# STM32MP13xx register map
File version: 1.7
CPU: CA7 r0p0, little endian, MPU, FPU, 4 interrupt priority bits
Registers are 32-bit, read-write, reset 0x0 unless marked. A register's access mark holds for its fields unless they carry their own. Offsets are from the block's base; [hi:lo] are bit positions; {n}, {i} and the like mark numbered series; 'fields as' and 'values as' point back to an identical list; <NAME> marks a mode.

## DMA1
Base 0x48000000
Same registers: DMA2 0x48001000, DMA3 0x48005000
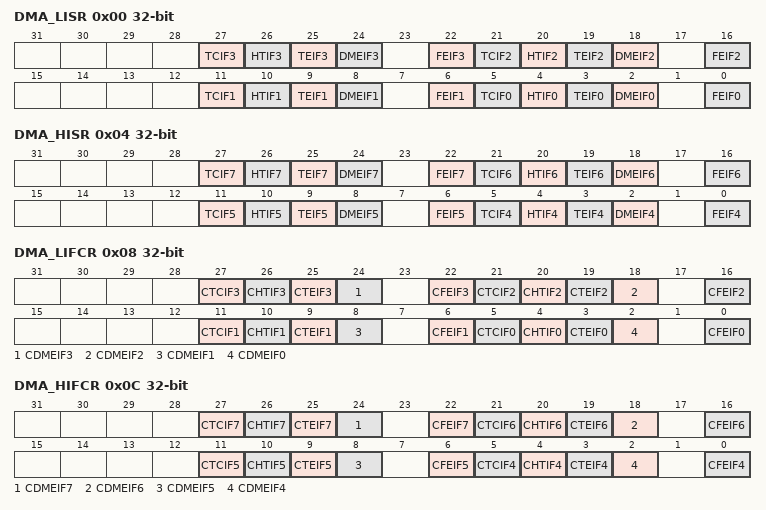
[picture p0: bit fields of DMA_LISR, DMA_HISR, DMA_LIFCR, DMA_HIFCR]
0x00 DMA_LISR ro — DMA low interrupt status register
  [27] TCIF3 — stream x transfer complete interrupt flag (x = 3 to 0) This bit is set by hardware. It is cleared by software writing 1 to the corresponding bit in the DMA_LIFCR register.
    0=no transfer complete event on stream x; 1=a transfer complete event occurred on stream x
  [26] HTIF3 — stream x half transfer interrupt flag (x = 3 to 0) This bit is set by hardware. It is cleared by software writing 1 to the corresponding bit in the DMA_LIFCR register.
    0=no half transfer event on stream x; 1=a half transfer event occurred on stream x
  [25] TEIF3 — stream x transfer error interrupt flag (x = 3 to 0) This bit is set by hardware. It is cleared by software writing 1 to the corresponding bit in the DMA_LIFCR register.
    0=no transfer error on stream x; 1=a transfer error occurred on stream x
  [24] DMEIF3 — stream x direct mode error interrupt flag (x = 3 to 0) This bit is set by hardware. It is cleared by software writing 1 to the corresponding bit in the DMA_LIFCR register.
    0=No direct mode error on stream x; 1=a direct mode error occurred on stream x
  [22] FEIF3 — stream x FIFO error interrupt flag (x = 3 to 0) This bit is set by hardware. It is cleared by software writing 1 to the corresponding bit in the DMA_LIFCR register.
    0=no FIFO error event on stream x; 1=a FIFO error event occurred on stream x
  [21] TCIF2 — stream x transfer complete interrupt flag (x = 3 to 0) This bit is set by hardware. It is cleared by software writing 1 to the corresponding bit in the DMA_LIFCR register.
    values as TCIF3
  [20] HTIF2 — stream x half transfer interrupt flag (x = 3 to 0) This bit is set by hardware. It is cleared by software writing 1 to the corresponding bit in the DMA_LIFCR register.
    values as HTIF3
  [19] TEIF2 — stream x transfer error interrupt flag (x = 3 to 0) This bit is set by hardware. It is cleared by software writing 1 to the corresponding bit in the DMA_LIFCR register.
    values as TEIF3
  [18] DMEIF2 — stream x direct mode error interrupt flag (x = 3 to 0) This bit is set by hardware. It is cleared by software writing 1 to the corresponding bit in the DMA_LIFCR register.
    values as DMEIF3
  [16] FEIF2 — stream x FIFO error interrupt flag (x = 3 to 0) This bit is set by hardware. It is cleared by software writing 1 to the corresponding bit in the DMA_LIFCR register.
    values as FEIF3
  [11] TCIF1 — stream x transfer complete interrupt flag (x = 3 to 0) This bit is set by hardware. It is cleared by software writing 1 to the corresponding bit in the DMA_LIFCR register.
    values as TCIF3
  [10] HTIF1 — stream x half transfer interrupt flag (x = 3 to 0) This bit is set by hardware. It is cleared by software writing 1 to the corresponding bit in the DMA_LIFCR register.
    values as HTIF3
  [9] TEIF1 — stream x transfer error interrupt flag (x = 3 to 0) This bit is set by hardware. It is cleared by software writing 1 to the corresponding bit in the DMA_LIFCR register.
    values as TEIF3
  [8] DMEIF1 — stream x direct mode error interrupt flag (x = 3 to 0) This bit is set by hardware. It is cleared by software writing 1 to the corresponding bit in the DMA_LIFCR register.
    values as DMEIF3
  [6] FEIF1 — stream x FIFO error interrupt flag (x = 3 to 0) This bit is set by hardware. It is cleared by software writing 1 to the corresponding bit in the DMA_LIFCR register.
    values as FEIF3
  [5] TCIF0 — stream x transfer complete interrupt flag (x = 3 to 0) This bit is set by hardware. It is cleared by software writing 1 to the corresponding bit in the DMA_LIFCR register.
    values as TCIF3
  [4] HTIF0 — stream x half transfer interrupt flag (x = 3 to 0) This bit is set by hardware. It is cleared by software writing 1 to the corresponding bit in the DMA_LIFCR register.
    values as HTIF3
  [3] TEIF0 — stream x transfer error interrupt flag (x = 3 to 0) This bit is set by hardware. It is cleared by software writing 1 to the corresponding bit in the DMA_LIFCR register.
    values as TEIF3
  [2] DMEIF0 — stream x direct mode error interrupt flag (x = 3 to 0) This bit is set by hardware. It is cleared by software writing 1 to the corresponding bit in the DMA_LIFCR register.
    values as DMEIF3
  [0] FEIF0 — stream x FIFO error interrupt flag (x = 3 to 0) This bit is set by hardware. It is cleared by software writing 1 to the corresponding bit in the DMA_LIFCR register.
    values as FEIF3
0x04 DMA_HISR ro — DMA high interrupt status register
  [27] TCIF7 — stream x transfer complete interrupt flag (x = 7 to 4) This bit is set by hardware. It is cleared by software writing 1 to the corresponding bit in the DMA_HIFCR register.
    values as DMA_LISR.TCIF3
  [26] HTIF7 — stream x half transfer interrupt flag (x = 7 to 4) This bit is set by hardware. It is cleared by software writing 1 to the corresponding bit in the DMA_HIFCR register.
    values as DMA_LISR.HTIF3
  [25] TEIF7 — stream x transfer error interrupt flag (x = 7 to 4) This bit is set by hardware. It is cleared by software writing 1 to the corresponding bit in the DMA_HIFCR register.
    values as DMA_LISR.TEIF3
  [24] DMEIF7 — stream x direct mode error interrupt flag (x = 7 to 4) This bit is set by hardware. It is cleared by software writing 1 to the corresponding bit in the DMA_HIFCR register.
    0=no direct mode error on stream x; 1=a direct mode error occurred on stream x
  [22] FEIF7 — stream x FIFO error interrupt flag (x = 7 to 4) This bit is set by hardware. It is cleared by software writing 1 to the corresponding bit in the DMA_HIFCR register.
    values as DMA_LISR.FEIF3
  [21] TCIF6 — stream x transfer complete interrupt flag (x = 7 to 4) This bit is set by hardware. It is cleared by software writing 1 to the corresponding bit in the DMA_HIFCR register.
    values as DMA_LISR.TCIF3
  [20] HTIF6 — stream x half transfer interrupt flag (x = 7 to 4) This bit is set by hardware. It is cleared by software writing 1 to the corresponding bit in the DMA_HIFCR register.
    values as DMA_LISR.HTIF3
  [19] TEIF6 — stream x transfer error interrupt flag (x = 7 to 4) This bit is set by hardware. It is cleared by software writing 1 to the corresponding bit in the DMA_HIFCR register.
    values as DMA_LISR.TEIF3
  [18] DMEIF6 — stream x direct mode error interrupt flag (x = 7 to 4) This bit is set by hardware. It is cleared by software writing 1 to the corresponding bit in the DMA_HIFCR register.
    values as DMEIF7
  [16] FEIF6 — stream x FIFO error interrupt flag (x = 7 to 4) This bit is set by hardware. It is cleared by software writing 1 to the corresponding bit in the DMA_HIFCR register.
    values as DMA_LISR.FEIF3
  [11] TCIF5 — stream x transfer complete interrupt flag (x = 7 to 4) This bit is set by hardware. It is cleared by software writing 1 to the corresponding bit in the DMA_HIFCR register.
    values as DMA_LISR.TCIF3
  [10] HTIF5 — stream x half transfer interrupt flag (x = 7 to 4) This bit is set by hardware. It is cleared by software writing 1 to the corresponding bit in the DMA_HIFCR register.
    values as DMA_LISR.HTIF3
  [9] TEIF5 — stream x transfer error interrupt flag (x = 7 to 4) This bit is set by hardware. It is cleared by software writing 1 to the corresponding bit in the DMA_HIFCR register.
    values as DMA_LISR.TEIF3
  [8] DMEIF5 — stream x direct mode error interrupt flag (x = 7 to 4) This bit is set by hardware. It is cleared by software writing 1 to the corresponding bit in the DMA_HIFCR register.
    values as DMEIF7
  [6] FEIF5 — stream x FIFO error interrupt flag (x = 7 to 4) This bit is set by hardware. It is cleared by software writing 1 to the corresponding bit in the DMA_HIFCR register.
    values as DMA_LISR.FEIF3
  [5] TCIF4 — stream x transfer complete interrupt flag (x = 7 to 4) This bit is set by hardware. It is cleared by software writing 1 to the corresponding bit in the DMA_HIFCR register.
    values as DMA_LISR.TCIF3
  [4] HTIF4 — stream x half transfer interrupt flag (x = 7 to 4) This bit is set by hardware. It is cleared by software writing 1 to the corresponding bit in the DMA_HIFCR register.
    values as DMA_LISR.HTIF3
  [3] TEIF4 — stream x transfer error interrupt flag (x = 7 to 4) This bit is set by hardware. It is cleared by software writing 1 to the corresponding bit in the DMA_HIFCR register.
    values as DMA_LISR.TEIF3
  [2] DMEIF4 — stream x direct mode error interrupt flag (x = 7 to 4) This bit is set by hardware. It is cleared by software writing 1 to the corresponding bit in the DMA_HIFCR register.
    values as DMEIF7
  [0] FEIF4 — stream x FIFO error interrupt flag (x = 7 to 4) This bit is set by hardware. It is cleared by software writing 1 to the corresponding bit in the DMA_HIFCR register.
    values as DMA_LISR.FEIF3
0x08 DMA_LIFCR wo — DMA low interrupt flag clear register
  [27] CTCIF3 — stream x clear transfer complete interrupt flag (x = 3 to 0) Writing 1 to this bit clears the corresponding TCIFx flag in the DMA_LISR register.
  [26] CHTIF3 — stream x clear half transfer interrupt flag (x = 3 to 0) Writing 1 to this bit clears the corresponding HTIFx flag in the DMA_LISR register
  [25] CTEIF3 — Stream x clear transfer error interrupt flag (x = 3 to 0) Writing 1 to this bit clears the corresponding TEIFx flag in the DMA_LISR register.
  [24] CDMEIF3 — stream x clear direct mode error interrupt flag (x = 3 to 0) Writing 1 to this bit clears the corresponding DMEIFx flag in the DMA_LISR register.
  [22] CFEIF3 — stream x clear FIFO error interrupt flag (x = 3 to 0) Writing 1 to this bit clears the corresponding CFEIFx flag in the DMA_LISR register.
  [21] CTCIF2 — stream x clear transfer complete interrupt flag (x = 3 to 0) Writing 1 to this bit clears the corresponding TCIFx flag in the DMA_LISR register.
  [20] CHTIF2 — stream x clear half transfer interrupt flag (x = 3 to 0) Writing 1 to this bit clears the corresponding HTIFx flag in the DMA_LISR register
  [19] CTEIF2 — Stream x clear transfer error interrupt flag (x = 3 to 0) Writing 1 to this bit clears the corresponding TEIFx flag in the DMA_LISR register.
  [18] CDMEIF2 — stream x clear direct mode error interrupt flag (x = 3 to 0) Writing 1 to this bit clears the corresponding DMEIFx flag in the DMA_LISR register.
  [16] CFEIF2 — stream x clear FIFO error interrupt flag (x = 3 to 0) Writing 1 to this bit clears the corresponding CFEIFx flag in the DMA_LISR register.
  [11] CTCIF1 — stream x clear transfer complete interrupt flag (x = 3 to 0) Writing 1 to this bit clears the corresponding TCIFx flag in the DMA_LISR register.
  [10] CHTIF1 — stream x clear half transfer interrupt flag (x = 3 to 0) Writing 1 to this bit clears the corresponding HTIFx flag in the DMA_LISR register
  [9] CTEIF1 — Stream x clear transfer error interrupt flag (x = 3 to 0) Writing 1 to this bit clears the corresponding TEIFx flag in the DMA_LISR register.
  [8] CDMEIF1 — stream x clear direct mode error interrupt flag (x = 3 to 0) Writing 1 to this bit clears the corresponding DMEIFx flag in the DMA_LISR register.
  [6] CFEIF1 — stream x clear FIFO error interrupt flag (x = 3 to 0) Writing 1 to this bit clears the corresponding CFEIFx flag in the DMA_LISR register.
  [5] CTCIF0 — stream x clear transfer complete interrupt flag (x = 3 to 0) Writing 1 to this bit clears the corresponding TCIFx flag in the DMA_LISR register.
  [4] CHTIF0 — stream x clear half transfer interrupt flag (x = 3 to 0) Writing 1 to this bit clears the corresponding HTIFx flag in the DMA_LISR register
  [3] CTEIF0 — Stream x clear transfer error interrupt flag (x = 3 to 0) Writing 1 to this bit clears the corresponding TEIFx flag in the DMA_LISR register.
  [2] CDMEIF0 — stream x clear direct mode error interrupt flag (x = 3 to 0) Writing 1 to this bit clears the corresponding DMEIFx flag in the DMA_LISR register.
  [0] CFEIF0 — stream x clear FIFO error interrupt flag (x = 3 to 0) Writing 1 to this bit clears the corresponding CFEIFx flag in the DMA_LISR register.
0x0C DMA_HIFCR wo — DMA high interrupt flag clear register
  [27] CTCIF7 — stream x clear transfer complete interrupt flag (x = 7 to 4) Writing 1 to this bit clears the corresponding TCIFx flag in the DMA_HISR register.
  [26] CHTIF7 — stream x clear half transfer interrupt flag (x = 7 to 4) Writing 1 to this bit clears the corresponding HTIFx flag in the DMA_HISR register.
  [25] CTEIF7 — stream x clear transfer error interrupt flag (x = 7 to 4) Writing 1 to this bit clears the corresponding TEIFx flag in the DMA_HISR register.
  [24] CDMEIF7 — stream x clear direct mode error interrupt flag (x = 7 to 4) Writing 1 to this bit clears the corresponding DMEIFx flag in the DMA_HISR register.
  [22] CFEIF7 — stream x clear FIFO error interrupt flag (x = 7 to 4) Writing 1 to this bit clears the corresponding CFEIFx flag in the DMA_HISR register.
  [21] CTCIF6 — stream x clear transfer complete interrupt flag (x = 7 to 4) Writing 1 to this bit clears the corresponding TCIFx flag in the DMA_HISR register.
  [20] CHTIF6 — stream x clear half transfer interrupt flag (x = 7 to 4) Writing 1 to this bit clears the corresponding HTIFx flag in the DMA_HISR register.
  [19] CTEIF6 — stream x clear transfer error interrupt flag (x = 7 to 4) Writing 1 to this bit clears the corresponding TEIFx flag in the DMA_HISR register.
  [18] CDMEIF6 — stream x clear direct mode error interrupt flag (x = 7 to 4) Writing 1 to this bit clears the corresponding DMEIFx flag in the DMA_HISR register.
  [16] CFEIF6 — stream x clear FIFO error interrupt flag (x = 7 to 4) Writing 1 to this bit clears the corresponding CFEIFx flag in the DMA_HISR register.
  [11] CTCIF5 — stream x clear transfer complete interrupt flag (x = 7 to 4) Writing 1 to this bit clears the corresponding TCIFx flag in the DMA_HISR register.
  [10] CHTIF5 — stream x clear half transfer interrupt flag (x = 7 to 4) Writing 1 to this bit clears the corresponding HTIFx flag in the DMA_HISR register.
  [9] CTEIF5 — stream x clear transfer error interrupt flag (x = 7 to 4) Writing 1 to this bit clears the corresponding TEIFx flag in the DMA_HISR register.
  [8] CDMEIF5 — stream x clear direct mode error interrupt flag (x = 7 to 4) Writing 1 to this bit clears the corresponding DMEIFx flag in the DMA_HISR register.
  [6] CFEIF5 — stream x clear FIFO error interrupt flag (x = 7 to 4) Writing 1 to this bit clears the corresponding CFEIFx flag in the DMA_HISR register.
  [5] CTCIF4 — stream x clear transfer complete interrupt flag (x = 7 to 4) Writing 1 to this bit clears the corresponding TCIFx flag in the DMA_HISR register.
  [4] CHTIF4 — stream x clear half transfer interrupt flag (x = 7 to 4) Writing 1 to this bit clears the corresponding HTIFx flag in the DMA_HISR register.
  [3] CTEIF4 — stream x clear transfer error interrupt flag (x = 7 to 4) Writing 1 to this bit clears the corresponding TEIFx flag in the DMA_HISR register.
  [2] CDMEIF4 — stream x clear direct mode error interrupt flag (x = 7 to 4) Writing 1 to this bit clears the corresponding DMEIFx flag in the DMA_HISR register.
  [0] CFEIF4 — stream x clear FIFO error interrupt flag (x = 7 to 4) Writing 1 to this bit clears the corresponding CFEIFx flag in the DMA_HISR register.
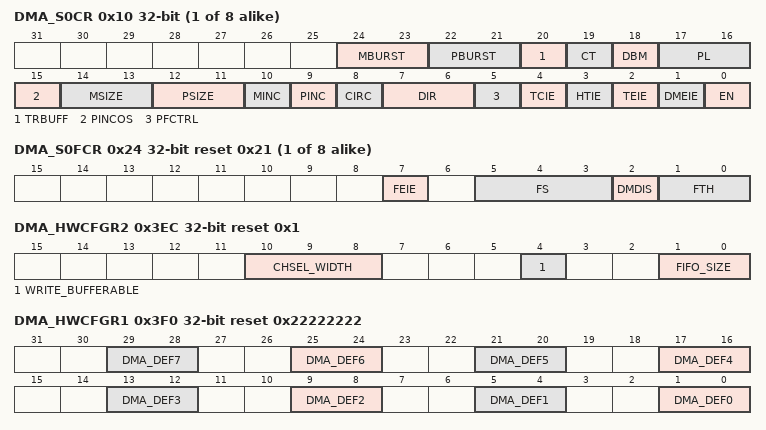
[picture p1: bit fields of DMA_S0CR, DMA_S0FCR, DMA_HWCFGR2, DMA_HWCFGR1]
{0x10+0x18*i} DMA_S{i}CR (i=0..7) — DMA stream {i} configuration register
  [24:23] MBURST — memory burst transfer configuration These bits are set and cleared by software. These bits are protected and can be written only if EN = 0. In direct mode, these bits are forced to 0x0 by hardware as soon as bit EN = 1.
    0=single transfer; 1=INCR4 (incremental burst of 4 beats); 2=INCR8 (incremental burst of 8 beats); 3=INCR16 (incremental burst of 16 beats)
  [22:21] PBURST — peripheral burst transfer configuration These bits are set and cleared by software. These bits are protected and can be written only if EN = 0. In direct mode, these bits are forced to 0x0 by hardware.
    values as MBURST
  [20] TRBUFF — Enable the DMA to handle bufferable transfers. Note: This bit must be set to 1 if the DMA stream manages UART/USART/LPUART transfers.
    0=bufferable transfers not enabled; 1=bufferable transfers enabled
  [19] CT — current target (only in double-buffer mode) This bit is set and cleared by hardware. It can also be written by software. This bit can be written only if EN = 0 to indicate the target memory area of the first transfer. Once the stream is enabled, this bit operates as a status flag indicating which memory area is the current target.
    0=current target memory is Memory 0 (addressed by the DMA_SxM0AR pointer); 1=current target memory is Memory 1 (addressed by the DMA_SxM1AR pointer)
  [18] DBM — double-buffer mode This bit is set and cleared by software. This bit is protected and can be written only if EN = 0.
    0=no buffer switching at the end of transfer; 1=memory target switched at the end of the DMA transfer
  [17:16] PL — priority level These bits are set and cleared by software. These bits are protected and can be written only if EN = 0.
    0=low; 1=medium; 2=high; 3=very high
  [15] PINCOS — peripheral increment offset size This bit is set and cleared by software This bit has no meaning if bit PINC = 0. This bit is protected and can be written only if EN = 0. This bit is forced low by hardware when the stream is enabled (EN = 1) if the direct mode is selected or if PBURST are different from 00.
    0=The offset size for the peripheral address calculation is linked to the PSIZE; 1=The offset size for the peripheral address calculation is fixed to 4 (32-bit alignment)
  [14:13] MSIZE — memory data size These bits are set and cleared by software. These bits are protected and can be written only if EN = 0. In direct mode, MSIZE is forced by hardware to the same value as PSIZE as soon as EN = 1.
    0=byte (8-bit); 1=half-word (16-bit); 2=word (32-bit)
  [12:11] PSIZE — peripheral data size These bits are set and cleared by software. These bits are protected and can be written only if EN = 0.
    0=byte (8-bit); 1=half-word (16-bit); 2=word (32-bit)
  [10] MINC — memory increment mode This bit is set and cleared by software. This bit is protected and can be written only if EN = 0.
    0=memory address pointer is fixed; 1=memory address pointer is incremented after each data transfer (increment is done according to MSIZE)
  [9] PINC — peripheral increment mode This bit is set and cleared by software. This bit is protected and can be written only if EN = 0.
    0=peripheral address pointer fixed; 1=peripheral address pointer incremented after each data transfer (increment done according to PSIZE)
  [8] CIRC — circular mode This bit is set and cleared by software and can be cleared by hardware. When the peripheral is the flow controller (bit PFCTRL = 1) and the stream is enabled (EN = 1), then this bit is automatically forced by hardware to 0. It is automatically forced by hardware to 1 if the DBM bit is set, as soon as the stream is enabled (EN = 1).
    0=circular mode disabled; 1=circular mode enabled
  [7:6] DIR — data transfer direction These bits are set and cleared by software. These bits are protected and can be written only if EN = 0.
    0=peripheral-to-memory; 1=memory-to-peripheral; 2=memory-to-memory
  [5] PFCTRL — peripheral flow controller This bit is set and cleared by software. This bit is protected and can be written only if EN = 0. When the memory-to-memory mode is selected (bits DIR[1:0]=10), then this bit is automatically forced to 0 by hardware.
    0=DMA is the flow controller; 1=The peripheral is the flow controller
  [4] TCIE — transfer complete interrupt enable This bit is set and cleared by software.
    0=TC interrupt disabled; 1=TC interrupt enabled
  [3] HTIE — half transfer interrupt enable This bit is set and cleared by software.
    0=HT interrupt disabled; 1=HT interrupt enabled
  [2] TEIE — transfer error interrupt enable This bit is set and cleared by software.
    0=TE interrupt disabled; 1=TE interrupt enabled
  [1] DMEIE — direct mode error interrupt enable This bit is set and cleared by software.
    0=DME interrupt disabled; 1=DME interrupt enabled
  [0] EN — stream enable / flag stream ready when read low This bit is set and cleared by software. This bit may be cleared by hardware: on a DMA end of transfer (stream ready to be configured) if a transfer error occurs on the AHB master buses when the FIFO threshold on memory AHB port is not compatible with the size of the burst When this bit is read as 0, the software is allowed to program the configuration and FIFO bits registers. It is forbidden to write these registers when the EN bit is read as 1. Note: Before setting EN bit to 1 to start a new transfer, the event flags corresponding to the stream in DMA_LISR or DMA_HISR register must be cleared.
    0=stream disabled; 1=stream enabled
{0x14+0x18*i} DMA_S{i}NDTR (i=0..7) — DMA stream {i} number of data register
  [15:0] NDT — number of data items to transfer (0 up to 65535) This register can be written only when the stream is disabled. When the stream is enabled, this register is read-only, indicating the remaining data items to be transmitted. This register decrements after each DMA transfer. Once the transfer is completed, this register can either stay at zero (when the stream is in normal mode) or be reloaded automatically with the previously programmed value in the following cases: when the stream is configured in circular mode. when the stream is enabled again by setting EN bit to 1. If the value of this register is zero, no transaction can be served even if the stream is enabled.
{0x18+0x18*i} DMA_S{i}PAR (i=0..7) — DMA stream {i} peripheral address register
  [31:0] PAR — peripheral address Base address of the peripheral data register from/to which the data is read/written. These bits are write-protected and can be written only when bit EN = 0 in DMA_SxCR.
{0x1C+0x18*i} DMA_S{i}M0AR (i=0..7) — DMA stream {i} memory 0 address register
  [31:0] M0A — memory 0 address Base address of memory area 0 from/to which the data is read/written. These bits are write-protected. They can be written only if: the stream is disabled (EN = 0 in DMA_SxCR) or the stream is enabled (EN = 1 in DMA_SxCR) and CT = 1 in DMA_SxCR (in double-buffer mode).
{0x20+0x18*i} DMA_S{i}M1AR (i=0..7) — DMA stream {i} memory 1 address register
  [31:0] M1A — memory 1 address (used in case of double-buffer mode) Base address of memory area 1 from/to which the data is read/written. This register is used only for the double-buffer mode. These bits are write-protected. They can be written only if: the stream is disabled (EN = 0 in DMA_SxCR) or the stream is enabled (EN = 1 in DMA_SxCR) and bit CT = 0 in DMA_SxCR .
{0x24+0x18*i} DMA_S{i}FCR access per field reset 0x21 (i=0..7) — DMA stream {i} FIFO control register
  [7] FEIE rw — FIFO error interrupt enable This bit is set and cleared by software.
    0=FE interrupt disabled; 1=FE interrupt enabled
  [5:3] FS ro — FIFO status These bits are read-only. others: no meaning These bits are not relevant in the direct mode (DMDIS = 0).
    0=0 < fifo_level < 1/4; 1=1/4 less than or equal to fifo_level < 1/2; 2=1/2 less than or equal to fifo_level < 3/4; 3=3/4 less than or equal to fifo_level < full; 4=FIFO is empty; 5=FIFO is full
  [2] DMDIS rw — direct mode disable This bit is set and cleared by software. It can be set by hardware. This bit is protected and can be written only if EN = 0. This bit is set by hardware if the memory-to-memory mode is selected (DIR bit in DMA_SxCR are 10) and the EN = 1 in DMA_SxCR because the direct mode is not allowed in the memory-to-memory configuration.
    0=direct mode enabled; 1=direct mode disabled
  [1:0] FTH rw — FIFO threshold selection These bits are set and cleared by software. These bits are not used in the direct mode when the DMIS = 0. These bits are protected and can be written only if EN = 0.
    0=1/4 full FIFO; 1=1/2 full FIFO; 2=3/4 full FIFO; 3=full FIFO
0x3EC DMA_HWCFGR2 ro reset 0x1 — DMA hardware configuration 2 register
  [10:8] CHSEL_WIDTH — bit width of the CHSEL field of any DMA_SxCR register common to all streams In [0..6] range: 2: up to 8 channels programmable selection 3: up to 16 channels programmable selection 4: up to 32 channels programmable selection 5: up to 64 channels programmable selection 6: up to 128 channels programmable selection
    0=no programmable selection; 1=2 channels programmable selection
  [4] WRITE_BUFFERABLE — In any case, DMA acknowledge signal is asserted one cycle after the address phase of the bus access on its AHB peripheral master port.
    0=DMA acknowledge signal is de-asserted one cycle after occurred both 1) the last cycle of the data phase of the bus access on its AHB peripheral master port and 2) the de-assertion of the peripheral request; 1=DMA acknowledge signal is de-asserted exactly one cycle after the last cycle of the data phase of the bus access on its AHB peripheral master port
  [1:0] FIFO_SIZE — FIFO size, common to all streams In [0..3] range: 2: 8-word FIFO 3: 16-word FIFO
    0=2-word FIFO; 1=4-word FIFO
0x3F0 DMA_HWCFGR1 ro reset 0x22222222 — DMA hardware configuration 1 register
  [all] fields
    0=none; 1=regular
  [4n+1:4n] DMA_DEF{n} (n=0..7) — type of the stream {n} 2: double-buffer 3: Reserved
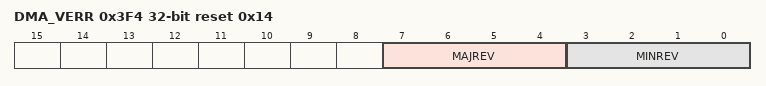
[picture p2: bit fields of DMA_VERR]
0x3F4 DMA_VERR ro reset 0x14 — DMA version register
  [7:4] MAJREV — major IP revision
  [3:0] MINREV — minor IP revision
0x3F8 DMA_IPDR ro reset 0x100002 — DMA identification register
  [31:0] ID — size identification This register identifies the peripheral.
0x3FC DMA_SIDR ro reset 0xA3C5DD01 — DMA size identification register
  [31:0] SID — size identification This register identifies the DMA as a peripheal with a size of 1 Kbyte address space.
